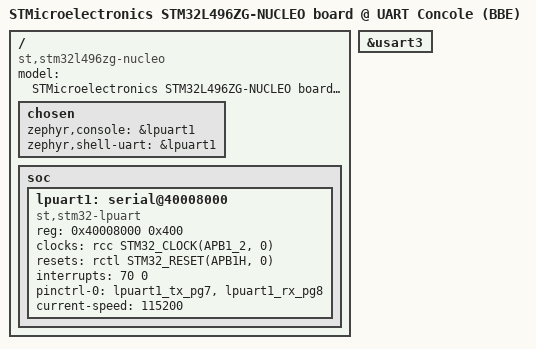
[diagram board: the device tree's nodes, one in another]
/*
 * Copyright (c) 2023-2026 TiaC Systems
 * SPDX-License-Identifier: Apache-2.0
 */

#include "../../zephyr/boards/st/nucleo_l496zg/nucleo_l496zg.dts"

/ {
	model = "STMicroelectronics STM32L496ZG-NUCLEO board @ UART Concole (BBE)";
	compatible = "st,stm32l496zg-nucleo",
		     "st,stm32l496zg-nucleo-bbe",
		     "st,stm32l496zg-nucleo-uartcons",
		     "st,stm32l496zg-nucleo-uartcons-bbe";

	chosen {
		zephyr,console = &lpuart1;
		zephyr,shell-uart = &lpuart1;
	};
};

/*
 * On ST Nucleo L496ZG pin D0 (RX) and D1 (TX) are connected to USART3 and
 * not to LPUART1 as set in the origin upstream Devicetree. For more details,
 * see schematic MB1312-A03 on sheet 5 and manual UM2179 table 11 on page 40.
 */

/delete-node/ &arduino_serial;
arduino_serial: &usart3 {};

/*
 * Setup LPUART1 again, because it was removed completely by /delete-node/.
 * There is (as yet) no way to delete or move only a node label, for details
 * see: https://github.com/devicetree-org/devicetree-specification/issues/64
 *
 * NOTE: copy and own from original devicetree atrefacts in
 * "zephyr/boards/st/nucleo_l496zg/nucleo_l496zg.dts" and
 * "zephyr/dts/st/l4/stm32l4.dtsi"
 */

/ {
	soc {
		lpuart1: serial@40008000 {
			compatible = "st,stm32-lpuart", "st,stm32-uart";
			reg = <0x40008000 0x400>;
			clocks = <&rcc STM32_CLOCK(APB1_2, 0)>;
			resets = <&rctl STM32_RESET(APB1H, 0)>;
			interrupts = <70 0>;
			status = "disabled";
		};
	};
};

&lpuart1 {
	pinctrl-0 = <&lpuart1_tx_pg7 &lpuart1_rx_pg8>;
	pinctrl-names = "default";
	current-speed = <115200>;
	status = "okay";
};
